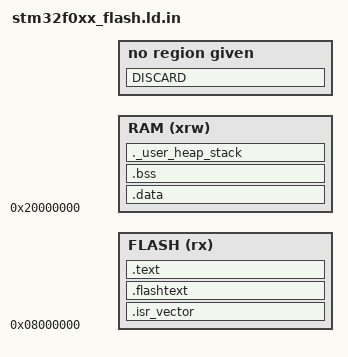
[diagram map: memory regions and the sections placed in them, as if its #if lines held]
/*
Template linker script for F0xx.
Expected to be preprocessed to determine some memory sizes and a few additional
features:
RAM_SIZE :: Available RAM
FLASH_SIZE :: Available flash
FLASH_SETTINGS_SIZE :: Subtracted from FLASH_SIZE, additional memory area
ENABLE_LIBC_INIT_ARRAY :: If defined, include C++ constructors and vtable init
*/

ENTRY(Reset_Handler)

_estack = 0x20000000 + RAM_SIZE;

_Min_Heap_Size = 0;
_Min_Stack_Size = 0x100;

MEMORY
{
  RAM (xrw)        : ORIGIN = 0x20000000, LENGTH = RAM_SIZE
#ifdef FLASH_SETTINGS_SIZE
  FLASH (rx)       : ORIGIN = 0x08000000, LENGTH = FLASH_SIZE - FLASH_SETTINGS_SIZE
#else
  FLASH (rx)       : ORIGIN = 0x08000000, LENGTH = FLASH_SIZE
#endif
}

SECTIONS
{
  .isr_vector :
  {
    . = ALIGN(16);
    KEEP(*(.isr_vector))            /* Startup code */
    . = ALIGN(16);
  } >FLASH

  .flashtext :
  {
    . = ALIGN(16);
    *(.flashtext)            /* Startup code */
    . = ALIGN(16);
  } >FLASH

  .text :
  {
    . = ALIGN(16);
    *(.text)                   /* remaining code */
    *(.text.*)                 /* remaining code */
    *(.rodata)                 /* read-only data (constants) */
    *(.rodata*)
    *(.glue_7)
    *(.glue_7t)
    KEEP (*(.init))
    KEEP (*(.fini))

#ifdef ENABLE_LIBC_INIT_ARRAY
    . = ALIGN(16);
    __init_array_start = .;
    KEEP(*(.init_array))      /* C++ constructors */
    KEEP(*(.ctors))           /* and vtable init */
    __init_array_end = .;
#endif
    . = ALIGN(16);
     _etext = .;
     _sidata = _etext;
  } >FLASH
  
  .data : AT ( _sidata )
  {
    . = ALIGN(16);
    _sdata = . ;
    *(.ramtext*)
    . = ALIGN(16);
    *(.data*)
    *(.data.*)
    . = ALIGN(16);
     _edata = . ;
  } >RAM

  .bss :
  {
    . = ALIGN(16);
    _sbss = .;
    *(.bss)
    *(.bss*)
    *(COMMON)
    . = ALIGN(16);
   _ebss = . ;
  } >RAM
  
  PROVIDE ( end = _ebss );
  PROVIDE ( _end = _ebss );
  
  ._user_heap_stack :
  {
    . = ALIGN(16);
    PROVIDE ( end = . );
    PROVIDE ( _end = . );
    . = . + _Min_Heap_Size;
    . = . + _Min_Stack_Size;
    . = ALIGN(16);
  } >RAM

  DISCARD :
  {
    libc.a ( * )
    libm.a ( * )
    libgcc.a ( * )
  }
}
